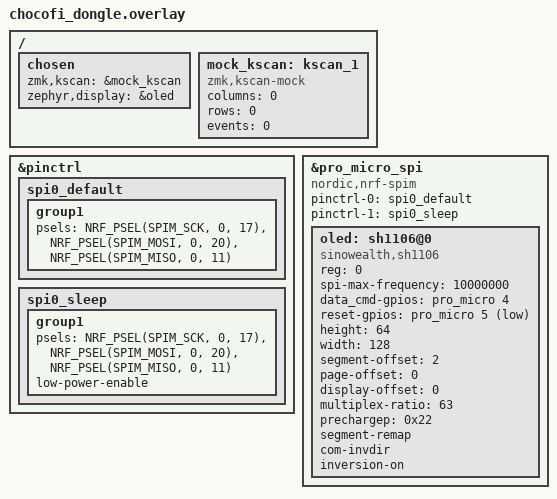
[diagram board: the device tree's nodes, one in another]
#include "chocofi.dtsi"

/ {
    chosen {
        zmk,kscan = &mock_kscan;
        zephyr,display = &oled;
    };

    mock_kscan: kscan_1 {
        compatible = "zmk,kscan-mock";
        columns = <0>;
        rows = <0>;
        events = <0>;
    };
};

/delete-node/ &default_kscan;

&pinctrl {
    spi0_default: spi0_default {
        group1 {
            psels = <NRF_PSEL(SPIM_SCK, 0, 17)>,
                    <NRF_PSEL(SPIM_MOSI, 0, 20)>,
                    <NRF_PSEL(SPIM_MISO, 0, 11)>;
        };
    };

    spi0_sleep: spi0_sleep {
        group1 {
            psels = <NRF_PSEL(SPIM_SCK, 0, 17)>,
                    <NRF_PSEL(SPIM_MOSI, 0, 20)>,
                    <NRF_PSEL(SPIM_MISO, 0, 11)>;
                    low-power-enable;
        };
    };
};

&pro_micro_spi {
    status = "okay";
    compatible = "nordic,nrf-spim";
    pinctrl-0 = <&spi0_default>;
    pinctrl-1 = <&spi0_sleep>;
    pinctrl-names = "default", "sleep";

    oled: sh1106@0 {
        compatible = "sinowealth,sh1106";
        reg = <0>;
        spi-max-frequency = <10000000>;
        data_cmd-gpios = <&pro_micro 4 0>;
        reset-gpios = <&pro_micro 5 GPIO_ACTIVE_LOW>;
        height = <64>;aa
        width = <128>;
        segment-offset = <2>;
        page-offset = <0>;
        display-offset = <0>;
        multiplex-ratio = <63>;
        prechargep = <0x22>;
        segment-remap;
		com-invdir;
        inversion-on;
    };
};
